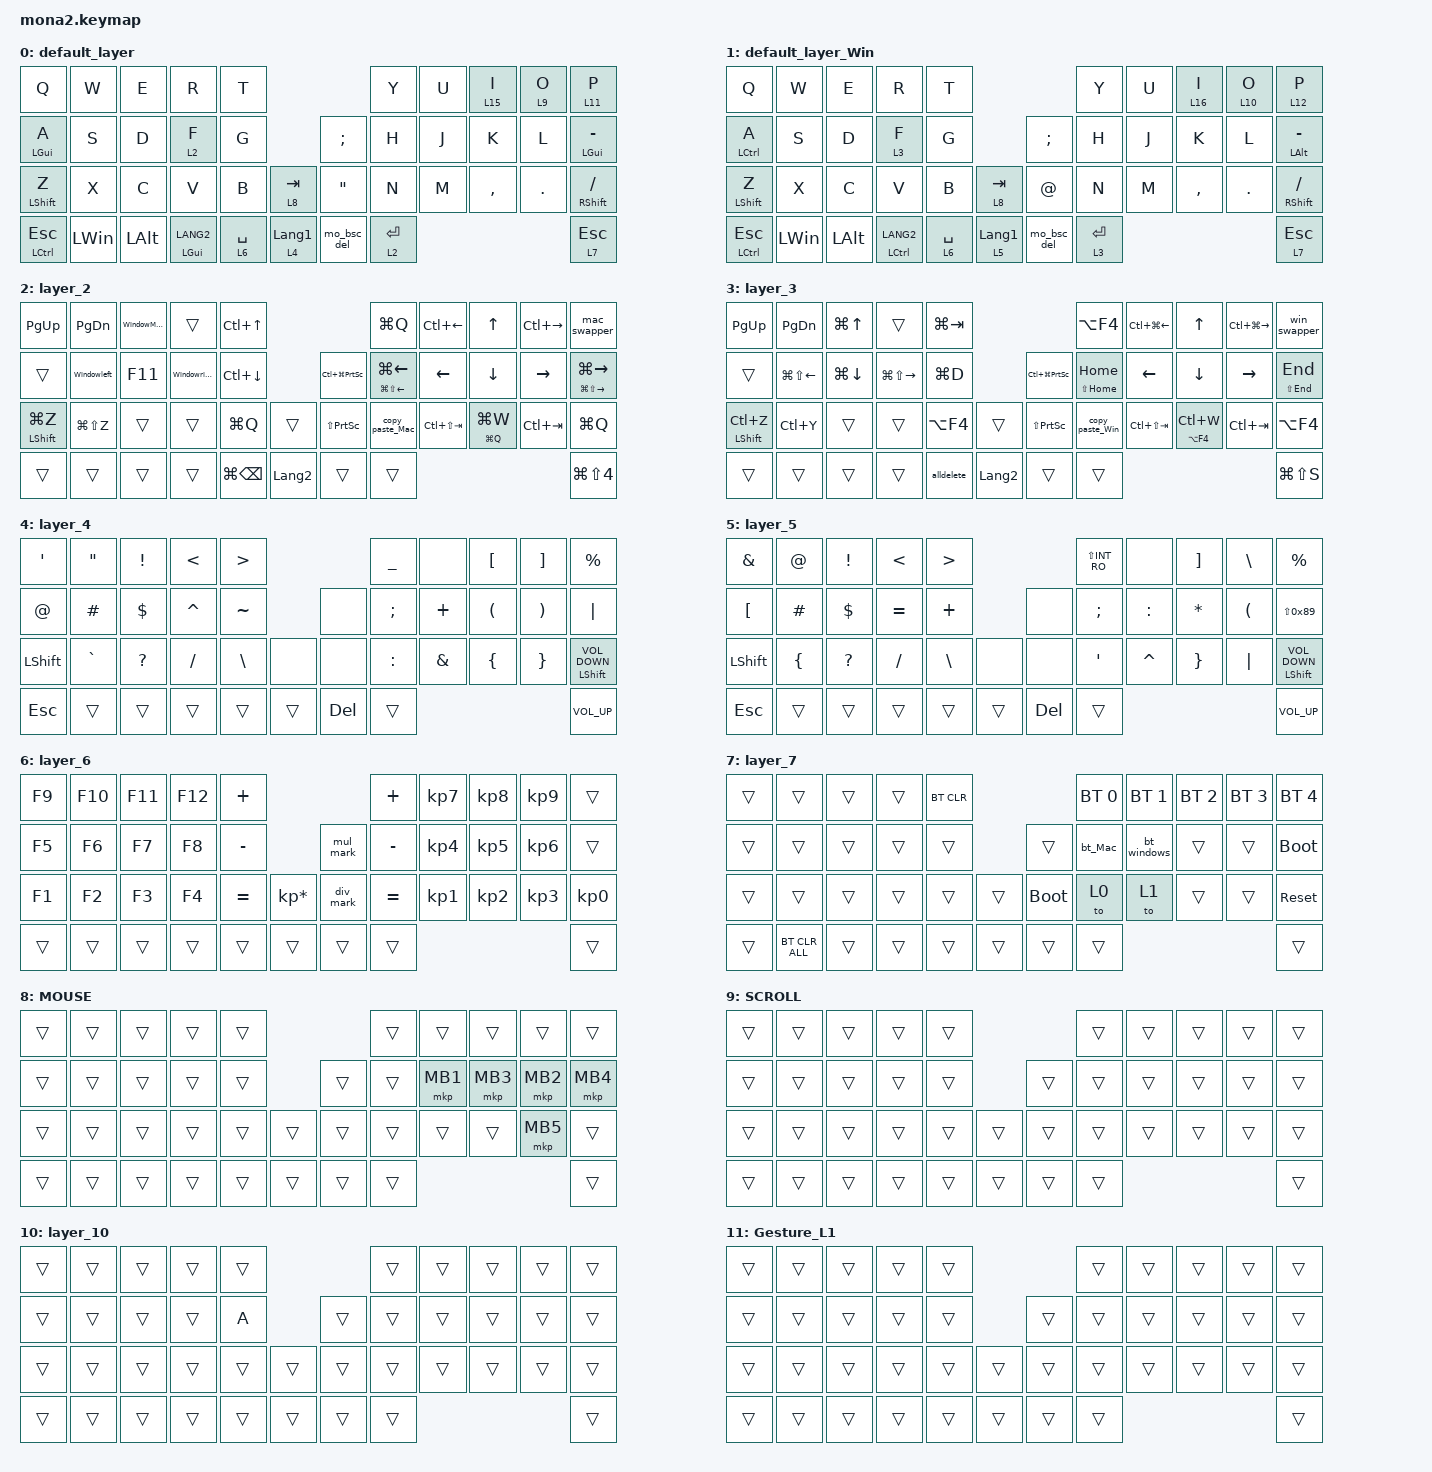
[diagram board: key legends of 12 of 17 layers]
#include <input/processors.dtsi>
#include <dt-bindings/zmk/input_transform.h>
#include <zephyr/dt-bindings/input/input-event-codes.h>
#include <mouse-gesture.dtsi>
#include <zephyr/dt-bindings/input/input-event-codes.h>
#include <behaviors.dtsi>
#include <dt-bindings/zmk/bt.h>
#include <dt-bindings/zmk/keys.h>
#include <dt-bindings/zmk/pointing.h>

//#include "gesture/gesture_L1.dtsi"
//#include "gesture/gesture_L2.dtsi"
//#include "gesture/gesture_L3.dtsi"

#define ZMK_POINTING_DEFAULT_SCRL_VAL 100
#define MOUSE 5

// OS設定を日本語キーボードのまま使用するための変換定義

#define JP_DQUOTE       AT                // "
#define JP_AMPERSAND    CARET             // &
#define JP_QUOTE        AMPERSAND         // '
#define JP_EQUAL        UNDER             // =
#define JP_CARET        EQUAL             // ^
#define JP_YEN          0x89              // ¥
#define JP_PLUS         COLON             // +
#define JP_TILDE        PLUS              // ~
#define JP_PIPE         LS(0x89)          // |
#define JP_AT           LEFT_BRACKET      // @
#define JP_COLON        SINGLE_QUOTE      // :
#define JP_ASTERISK     DOUBLE_QUOTES     // *
#define JP_BACKQUOTE    LEFT_BRACE        // `
#define JP_UNDERSCORE   LS(0x87)          // _
#define JP_LBRACKET     RIGHT_BRACKET     // [
#define JP_RBRACKET     BACKSLASH         // ]
#define JP_LPAREN       ASTERISK          // (
#define JP_RPAREN       LEFT_PARENTHESIS  // )
#define JP_LBRACE       RIGHT_BRACE       // {
#define JP_RBRACE       PIPE              // }
#define JP_KANA         LANGUAGE_1        // かな
#define JP_EISU         LANGUAGE_2        // 英数
#define JP_HANZEN       GRAVE             // 半角/全角

&mt {
    flavor = "balanced";
    quick-tap-ms = <250>;
};

&lt {
    tapping-term-ms = <180>; /* タップ判定時間 */
    quick-tap-ms = <200>; /* クイックタップ時間(連続タップ判定時間) */
    flavor = "balanced";
};

/ {
    combos {
        compatible = "zmk,combos";

        a {
            bindings = <&none>;
            key-positions = <17 29 18 19 31 10 21>;
        };

        tab {
            bindings = <&kp TAB>;
            key-positions = <11 12>;
        };

        esc {
            bindings = <&kp ESC>;
            key-positions = <2 1>;
        };

        f10 {
            bindings = <&kp F10>;
            key-positions = <23 24>;
        };

        Layer13 {
            bindings = <&lt 13 LG(TAB)>;
            key-positions = <8 9>;
            layers = <0>;
        };

        Layer15 {
            bindings = <&kp TAB>;
            key-positions = <19 18>;
            layers = <0 1 8>;
        };

        layer14 {
            bindings = <&lt 14 LA(TAB)>;
            key-positions = <8 9>;
            layers = <1>;
        };

        Spotlight {
            bindings = <&kp LG(SPACE)>;
            key-positions = <8 7>;
            layers = <0>;
        };

        search {
            bindings = <&kp LEFT_GUI>;
            key-positions = <8 7>;
            layers = <1>;
        };

        command_c {
            bindings = <&command_c>;
            key-positions = <18 17>;
            layers = <2>;
        };

        command_v {
            bindings = <&command_v>;
            key-positions = <18 19>;
            layers = <2>;
        };

        control_c {
            bindings = <&control_c>;
            key-positions = <18 17>;
            layers = <3>;
        };

        control_v {
            bindings = <&control_v>;
            key-positions = <18 19>;
            layers = <3>;
        };

        command_z {
            bindings = <&kp LG(Z)>;
            key-positions = <21 22>;
            layers = <0>;
        };

        control_z {
            bindings = <&kp LC(Z)>;
            key-positions = <21 22>;
            layers = <1>;
        };

        command_y {
            bindings = <&kp LG(LS(Z))>;
            key-positions = <22 23>;
            layers = <0>;
        };

        control_y {
            bindings = <&kp LC(Y)>;
            key-positions = <22 23>;
            layers = <1>;
        };

        missioncontrol {
            bindings = <&missioncontrol>;
            key-positions = <7 8>;
            layers = <2>;
        };

        Windows_tab {
            bindings = <&window_tab>;
            key-positions = <7 8>;
            layers = <3>;
        };

        buck {
            bindings = <&mkp MB4>;
            key-positions = <30 31>;
        };

        Buck2 {
            bindings = <&mkp MB4>;
            key-positions = <29 30>;
        };

        Layer7 {
            bindings = <&mo 7>;
            key-positions = <33 34>;
        };
    };

    macros {
        to_layer_0: to_layer_0 {
            compatible = "zmk,behavior-macro-one-param";
            #binding-cells = <1>;
            bindings = <&to 0 &macro_param_1to1 &kp MACRO_PLACEHOLDER>;
            label = "TO_LAYER_0";
        };

        mul_mark: x_sign_win {
            compatible = "zmk,behavior-macro";
            #binding-cells = <0>;
            wait-ms = <10>;
            tap-ms = <10>;
            bindings =
                <&macro_press>,
                <&kp LALT>,
                <&macro_tap>,
                <&kp KP_N0 &kp KP_N2 &kp KP_N1 &kp KP_N5>,
                <&macro_release>,
                <&kp LALT>;
        };

        div_mark: div_mark {
            compatible = "zmk,behavior-macro";
            label = "DIV_MARK";
            #binding-cells = <0>;
            wait-ms = <10>;
            tap-ms = <10>;
            bindings =
                <&macro_press>,
                <&kp LALT>,
                <&macro_tap>,
                <&kp KP_N0 &kp KP_N2 &kp KP_N4 &kp KP_N7>,
                <&macro_release>,
                <&kp LALT>;
        };

        exit_AML: exit_AML {
            compatible = "zmk,behavior-macro";
            wait-ms = <0>;
            tap-ms = <0>;
            #binding-cells = <0>;
            bindings = <&tog_off 9>;
            label = "exit_AML";
        };

        kp_exit_AML: kp_exit_AML {
            compatible = "zmk,behavior-macro-one-param";
            wait-ms = <0>;
            tap-ms = <0>;
            #binding-cells = <1>;
            bindings = <&macro_param_1to1 &kp MACRO_PLACEHOLDER &exit_AML>;
            label = "KP_exit_AML";
        };

        bt_Mac: bt_Mac {
            compatible = "zmk,behavior-macro";
            #binding-cells = <0>;
            bindings = <&macro_tap>, <&bt BT_SEL 0>, <&macro_tap>, <&to 0>;

            label = "BT_MAC";
        };

        bt_windows: bt_windows {
            compatible = "zmk,behavior-macro";
            #binding-cells = <0>;
            bindings = <&macro_tap>, <&bt BT_SEL 1>, <&macro_tap>, <&to 1>;

            label = "BT_WINDOWS";
        };

        WindowMaximize: WindowMaximize {
            compatible = "zmk,behavior-macro";
            #binding-cells = <0>;
            bindings =
                <&macro_press>,
                <&kp LCTRL &kp LEFT_ALT>,
                <&macro_tap>,
                <&kp ENTER>,
                <&macro_release>,
                <&kp LCTRL &kp LEFT_ALT>;

            label = "WINDOWMAXIMIZE";
        };

        Windowleft: Windowleft {
            compatible = "zmk,behavior-macro";
            #binding-cells = <0>;
            bindings =
                <&macro_press>,
                <&kp LCTRL &kp LEFT_ALT>,
                <&macro_tap>,
                <&kp LEFT_ARROW>,
                <&macro_release>,
                <&kp LCTRL &kp LEFT_ALT>;

            label = "WINDOWLEFT";
        };

        Windowright: Windowright {
            compatible = "zmk,behavior-macro";
            #binding-cells = <0>;
            bindings =
                <&macro_press>,
                <&kp LCTRL &kp LEFT_ALT>,
                <&macro_tap>,
                <&kp RIGHT_ARROW>,
                <&macro_release>,
                <&kp LCTRL &kp LEFT_ALT>;

            label = "WINDOWRIGHT";
        };

        alldelete: alldelete {
            compatible = "zmk,behavior-macro";
            #binding-cells = <0>;
            bindings =
                <&macro_press>,
                <&kp LSHFT>,
                <&macro_tap>,
                <&kp HOME>,
                <&macro_release>,
                <&kp LSHFT>,
                <&macro_tap>,
                <&kp BACKSPACE>;

            label = "ALLDELETE";
        };
    };

    behaviors {
        lt_to_layer_0: lt_to_layer_0 {
            compatible = "zmk,behavior-hold-tap";
            label = "LAYER_TAP_TO_0";
            #binding-cells = <2>;
            tapping-term-ms = <200>;
            bindings = <&mo>, <&to_layer_0>;
        };

        scroll_up_down: mouse_wheel_up_down {
            compatible = "zmk,behavior-sensor-rotate";
            #sensor-binding-cells = <0>;
            tap-ms = <20>;
            bindings = <&msc SCRL_DOWN>, <&msc SCRL_UP>;
        };

        scroll_right_left: mouse_wheel_right_left {
            compatible = "zmk,behavior-sensor-rotate";
            #sensor-binding-cells = <0>;
            tap-ms = <20>;
            bindings = <&msc SCRL_LEFT>, <&msc SCRL_RIGHT>;
        };

        tog_off: toggle_layer_off {
            compatible = "zmk,behavior-toggle-layer";
            #binding-cells = <1>;
            display-name = "Toggle Layer Off";
            toggle-mode = "off";
        };

        mt_exit_AML_on_tap: mt_exit_AML_on_tap {
            compatible = "zmk,behavior-hold-tap";
            label = "MT_exit_AML_ON_TAP";
            bindings = <&kp>, <&kp_exit_AML>;

            #binding-cells = <2>;
            tapping-term-ms = <200>;
            flavor = "balanced";
            quick-tap-ms = <200>;
        };

        eisu_kana: eisu_kana {
            compatible = "zmk,behavior-tap-dance";
            label = "EISU_KANA";
            #binding-cells = <0>;
            bindings = <&lt 6 LANGUAGE_1>, <&kp LANGUAGE_2>;

            tapping-term-ms = <180>;
        };

        copy_paste_Mac: copy_paste_Mac {
            compatible = "zmk,behavior-tap-dance";
            label = "COPY_PASTE_MAC";
            #binding-cells = <0>;
            tapping-term-ms = <250>;
            bindings = <&mt LG(X) LG(C)>, <&kp LG(V)>;
        };

        copy_paste_Win: copy_paste_Win {
            compatible = "zmk,behavior-tap-dance";
            label = "COPY_PASTE_WIN";
            #binding-cells = <0>;
            tapping-term-ms = <250>;
            bindings = <&mt LC(X) LC(C)>, <&kp LC(V)>;
        };

        new_behavior: new_behavior {
            compatible = "zmk,behavior-sensor-rotate-var";
            label = "NEW_BEHAVIOR";
            #sensor-binding-cells = <2>;
            bindings = <&kp>, <&kp>;
        };

        missioncontrol: missioncontrol {
            compatible = "zmk,behavior-tap-dance";
            label = "MISSIONCONTROL";
            #binding-cells = <0>;
            bindings = <&kp LC(UP_ARROW)>, <&kp LC(DOWN_ARROW)>;

            tapping-term-ms = <250>;
        };

        window_tab: window_tab {
            compatible = "zmk,behavior-tap-dance";
            label = "WINDOW_TAB";
            #binding-cells = <0>;
            bindings = <&kp LG(TAB)>, <&kp LG(D)>;

            tapping-term-ms = <250>;
        };

        command_c: command_c {
            compatible = "zmk,behavior-tap-dance";
            label = "COMMAND_C";
            #binding-cells = <0>;
            tapping-term-ms = <250>;
            bindings = <&kp LG(C)>, <&kp LG(X)>;
        };

        command_v: command_v {
            compatible = "zmk,behavior-tap-dance";
            label = "COMMAND_V";
            #binding-cells = <0>;
            tapping-term-ms = <250>;
            bindings = <&kp LG(V)>, <&kp LG(V)>;
        };

        control_c: control_c {
            compatible = "zmk,behavior-tap-dance";
            label = "CONTROL_C";
            #binding-cells = <0>;
            tapping-term-ms = <250>;
            bindings = <&kp LC(C)>, <&kp LC(X)>;
        };

        control_v: control_v {
            compatible = "zmk,behavior-tap-dance";
            label = "CONTROL_V";
            #binding-cells = <0>;
            tapping-term-ms = <250>;
            bindings = <&kp LC(V)>, <&kp LG(V)>;
        };

        scroll_up_down_win: scroll_up_down_win {
            compatible = "zmk,behavior-sensor-rotate";
            #sensor-binding-cells = <0>;
            tap-ms = <20>;
            bindings = <&msc SCRL_UP>, <&msc SCRL_DOWN>;

            label = "SCROLL_UP_DOWN_WIN";
        };

        // 「マック・スワッパー」の定義

        mac_swapper: mac_swapper {
            compatible = "zmk,behavior-smart-toggle";
            #binding-cells = <0>;
            bindings = <&kp LGUI>, <&kp TAB>;

            // 1つ目がホールド(Cmd)、2つ目が連打用(Tab)
            // ignored-key-positions = <8>;     // 隣のキー（逆送り用）を指定。※環境に合わせて番号を調整してください
        };

        win_swapper: win_swapper {
            compatible = "zmk,behavior-smart-toggle";
            #binding-cells = <0>;
            bindings = <&kp LALT>, <&kp TAB>;

            // ignored-key-positions = <8>;
        };

        mo_bsc_del: mo_bsc_del {
            compatible = "zmk,behavior-mod-morph";
            label = "MO_BSC_DEL";
            bindings = <&kp BACKSPACE>, <&kp DELETE>;

            #binding-cells = <0>;
            mods = <(MOD_RSFT|MOD_LSFT)>;
        };
    };

    keymap {
        compatible = "zmk,keymap";

        default_layer {
            bindings = <
&kp Q             &kp W         &kp E         &kp R               &kp T                                               &kp Y        &kp U  &lt 15 I   &lt 9 O  &lt 11 P
&mt LEFT_GUI A    &kp S         &kp D         &lt 2 F             &kp G                            &kp SEMICOLON      &kp H        &kp J  &kp K      &kp L    &mt LEFT_GUI MINUS
&mt LEFT_SHIFT Z  &kp X         &kp C         &kp V               &kp B        &lt 8 TAB           &kp DOUBLE_QUOTES  &kp N        &kp M  &kp COMMA  &kp DOT  &mt RIGHT_SHIFT SLASH
&mt LCTRL ESC     &kp LEFT_WIN  &kp LEFT_ALT  &mt LEFT_GUI LANG2  &lt 6 SPACE  &lt 4 LANGUAGE_1    &mo_bsc_del        &lt 2 ENTER                             &lt 7 ESCAPE
            >;

            sensor-bindings = <&scroll_up_down>;
        };

        default_layer_Win {
            bindings = <
&kp Q             &kp W         &kp E         &kp R                   &kp T                                           &kp Y        &kp U  &lt 16 I   &lt 10 O  &lt 12 P
&mt LCTRL A       &kp S         &kp D         &lt 3 F                 &kp G                            &kp SEMICOLON  &kp H        &kp J  &kp K      &kp L     &mt LEFT_ALT MINUS
&mt LEFT_SHIFT Z  &kp X         &kp C         &kp V                   &kp B        &lt 8 TAB           &kp AT_SIGN    &kp N        &kp M  &kp COMMA  &kp DOT   &mt RIGHT_SHIFT SLASH
&mt LCTRL ESC     &kp LEFT_WIN  &kp LEFT_ALT  &mt LEFT_CONTROL LANG2  &lt 6 SPACE  &lt 5 LANGUAGE_1    &mo_bsc_del    &lt 3 ENTER                              &lt 7 ESC
            >;

            sensor-bindings = <&scroll_up_down_win>;
        };

        layer_2 {
            bindings = <
&kp PAGE_UP      &kp PAGE_DOWN  &WindowMaximize  &trans        &kp LC(UP_ARROW)                                               &kp LG(Q)                              &kp LC(LEFT_ARROW)  &kp UP_ARROW     &kp LC(RIGHT_ARROW)  &mac_swapper
&trans           &Windowleft    &kp F11          &Windowright  &kp LC(DOWN_ARROW)                    &kp LC(LG(PRINTSCREEN))  &mt LG(LS(LEFT_ARROW)) LG(LEFT_ARROW)  &kp LEFT_ARROW      &kp DOWN_ARROW   &kp RIGHT_ARROW      &mt LG(LS(RIGHT_ARROW)) LG(RIGHT_ARROW)
&mt LSHFT LG(Z)  &kp LG(LS(Z))  &trans           &trans        &kp LG(Q)           &trans            &kp LS(PRINTSCREEN)      &copy_paste_Mac                        &kp LC(LS(TAB))     &mt LG(Q) LG(W)  &kp LC(TAB)          &kp LG(Q)
&trans           &trans         &trans           &trans        &kp LG(BACKSPACE)   &kp LANGUAGE_2    &trans                   &trans                                                                                           &kp LG(LS(NUMBER_4))
            >;

            sensor-bindings = <&inc_dec_kp LC(LS(TAB)) LC(TAB)>;
        };

        layer_3 {
            bindings = <
&kp PAGE_UP      &kp PAGE_DOWN     &kp LG(UP_ARROW)  &trans                   &kp LG(TAB)                                             &kp LA(F4)         &kp LC(LG(LEFT_ARROW))  &kp UP_ARROW      &kp LC(LG(RIGHT_ARROW))  &win_swapper
&trans           &kp LG(LS(LEFT))  &kp LG(DOWN)      &kp LG(LS(RIGHT_ARROW))  &kp LG(D)                      &kp LC(LG(PRINTSCREEN))  &mt LS(HOME) HOME  &kp LEFT_ARROW          &kp DOWN_ARROW    &kp RIGHT_ARROW          &mt LS(END) END
&mt LSHFT LC(Z)  &kp LC(Y)         &trans            &trans                   &kp LA(F4)   &trans            &kp LS(PRINTSCREEN)      &copy_paste_Win    &kp LC(LS(TAB))         &mt LA(F4) LC(W)  &kp LC(TAB)              &kp LA(F4)
&trans           &trans            &trans            &trans                   &alldelete   &kp LANGUAGE_2    &trans                   &trans                                                                                &kp LG(LS(S))
            >;

            sensor-bindings = <&inc_dec_kp LC(LS(TAB)) LC(TAB)>;
        };

        layer_4 {
            bindings = <
&kp SINGLE_QUOTE  &kp DOUBLE_QUOTES  &kp EXCLAMATION  &kp LESS_THAN  &kp GREATER_THAN                        &kp UNDERSCORE  &none     &kp LEFT_BRACKET      &kp RIGHT_BRACKET      &kp PERCENT
&kp AT_SIGN       &kp HASH           &kp DOLLAR       &kp CARET      &kp TILDE                   &none       &kp SEMICOLON   &kp PLUS  &kp LEFT_PARENTHESIS  &kp RIGHT_PARENTHESIS  &kp PIPE
&kp LSHIFT        &kp GRAVE          &kp QUESTION     &kp SLASH      &kp BACKSLASH     &none     &none       &kp COLON       &kp AMPS  &kp LEFT_BRACE        &kp RIGHT_BRACE        &mt LSHFT C_VOLUME_DOWN
&kp ESC           &trans             &trans           &trans         &trans            &trans    &kp DELETE  &trans                                                                 &kp C_VOLUME_UP
            >;

            sensor-bindings = <&inc_dec_kp LEFT_ARROW RIGHT_ARROW>;
        };

        layer_5 {
            bindings = <
&kp AMPS          &kp AT_SIGN     &kp EXCLAMATION  &kp LESS_THAN  &kp GREATER_THAN                        &kp LS(INT_RO)    &none      &kp RIGHT_BRACKET  &kp BACKSLASH         &kp PERCENT
&kp LEFT_BRACKET  &kp HASH        &kp DOLLAR       &kp EQUAL      &kp PLUS                    &none       &kp SEMICOLON     &kp COLON  &kp ASTERISK       &kp LEFT_PARENTHESIS  &kp LS(0x89)
&kp LSHIFT        &kp LEFT_BRACE  &kp QUESTION     &kp SLASH      &kp BACKSLASH     &none     &none       &kp SINGLE_QUOTE  &kp CARET  &kp RIGHT_BRACE    &kp PIPE              &mt LSHFT C_VOLUME_DOWN
&kp ESC           &trans          &trans           &trans         &trans            &trans    &kp DELETE  &trans                                                                &kp C_VOLUME_UP
            >;

            sensor-bindings = <&scroll_right_left>;
        };

        layer_6 {
            bindings = <
&kp F9  &kp F10  &kp F11  &kp F12  &kp PLUS                                 &kp PLUS   &kp KP_NUMBER_7  &kp KP_NUMBER_8  &kp KP_NUMBER_9  &trans
&kp F5  &kp F6   &kp F7   &kp F8   &kp MINUS                     &mul_mark  &kp MINUS  &kp KP_NUMBER_4  &kp KP_NUMBER_5  &kp KP_NUMBER_6  &trans
&kp F1  &kp F2   &kp F3   &kp F4   &kp EQUAL  &kp KP_MULTIPLY    &div_mark  &kp EQUAL  &kp KP_NUMBER_1  &kp KP_NUMBER_2  &kp KP_NUMBER_3  &kp KP_NUMBER_0
&trans  &trans   &trans   &trans   &trans     &trans             &trans     &trans                                                        &trans
            >;

            sensor-bindings = <&scroll_up_down>;
        };

        layer_7 {
            bindings = <
&trans  &trans          &trans  &trans  &bt BT_CLR                         &bt BT_SEL 0  &bt BT_SEL 1  &bt BT_SEL 2  &bt BT_SEL 3  &bt BT_SEL 4
&trans  &trans          &trans  &trans  &trans                &trans       &bt_Mac       &bt_windows   &trans        &trans        &bootloader
&trans  &trans          &trans  &trans  &trans      &trans    &bootloader  &to 0         &to 1         &trans        &trans        &sys_reset
&trans  &bt BT_CLR_ALL  &trans  &trans  &trans      &trans    &trans       &trans                                                  &trans
            >;

            sensor-bindings = <&scroll_up_down>;
        };

        MOUSE {
            bindings = <
&trans  &trans  &trans  &trans  &trans                    &trans  &trans    &trans    &trans    &trans
&trans  &trans  &trans  &trans  &trans            &trans  &trans  &mkp MB1  &mkp MB3  &mkp MB2  &mkp MB4
&trans  &trans  &trans  &trans  &trans  &trans    &trans  &trans  &trans    &trans    &mkp MB5  &trans
&trans  &trans  &trans  &trans  &trans  &trans    &trans  &trans                                &trans
            >;

            sensor-bindings = <&scroll_up_down>;
        };

        SCROLL {
            bindings = <
&trans  &trans  &trans  &trans  &trans                    &trans  &trans  &trans  &trans  &trans
&trans  &trans  &trans  &trans  &trans            &trans  &trans  &trans  &trans  &trans  &trans
&trans  &trans  &trans  &trans  &trans  &trans    &trans  &trans  &trans  &trans  &trans  &trans
&trans  &trans  &trans  &trans  &trans  &trans    &trans  &trans                          &trans
            >;

            sensor-bindings = <&inc_dec_kp LEFT_ARROW RIGHT_ARROW>;
        };

        layer_10 {
            bindings = <
&trans  &trans  &trans  &trans  &trans                    &trans  &trans  &trans  &trans  &trans
&trans  &trans  &trans  &trans  &kp A             &trans  &trans  &trans  &trans  &trans  &trans
&trans  &trans  &trans  &trans  &trans  &trans    &trans  &trans  &trans  &trans  &trans  &trans
&trans  &trans  &trans  &trans  &trans  &trans    &trans  &trans                          &trans
            >;

            sensor-bindings = <&inc_dec_kp LEFT_ARROW RIGHT_ARROW>;
        };

        Gesture_L1 {
            bindings = <
&trans  &trans  &trans  &trans  &trans                    &trans  &trans  &trans  &trans  &trans
&trans  &trans  &trans  &trans  &trans            &trans  &trans  &trans  &trans  &trans  &trans
&trans  &trans  &trans  &trans  &trans  &trans    &trans  &trans  &trans  &trans  &trans  &trans
&trans  &trans  &trans  &trans  &trans  &trans    &trans  &trans                          &trans
            >;

            sensor-bindings = <&inc_dec_kp UP_ARROW DOWN_ARROW>;
        };

        Gesture_L2 {
            bindings = <
&trans  &trans  &trans  &trans  &trans                    &trans  &trans  &trans  &trans  &trans
&trans  &trans  &trans  &trans  &trans            &trans  &trans  &trans  &trans  &trans  &trans
&trans  &trans  &trans  &trans  &trans  &trans    &trans  &trans  &trans  &trans  &trans  &trans
&trans  &trans  &trans  &trans  &trans  &trans    &trans  &trans                          &trans
            >;

            sensor-bindings = <&inc_dec_kp UP_ARROW DOWN_ARROW>;
        };

        Gesture_L3 {
            bindings = <
&trans  &trans  &trans  &trans  &trans                    &trans  &trans  &trans  &trans  &trans
&trans  &trans  &trans  &trans  &trans            &trans  &trans  &trans  &trans  &trans  &trans
&trans  &trans  &trans  &trans  &trans  &trans    &trans  &trans  &trans  &trans  &trans  &trans
&trans  &trans  &trans  &trans  &trans  &trans    &trans  &trans                          &trans
            >;
        };

        layer_14 {
            bindings = <
&trans  &trans  &trans  &trans  &trans                    &trans  &trans  &trans  &trans  &trans
&trans  &trans  &trans  &trans  &trans            &trans  &trans  &trans  &trans  &trans  &trans
&trans  &trans  &trans  &trans  &trans  &trans    &trans  &trans  &trans  &trans  &trans  &trans
&trans  &trans  &trans  &trans  &trans  &trans    &trans  &trans                          &trans
            >;
        };

        layer_15 {
            bindings = <
&trans  &trans  &trans  &trans  &trans                    &trans  &trans  &trans  &trans  &trans
&trans  &trans  &trans  &trans  &trans            &trans  &trans  &trans  &trans  &trans  &trans
&trans  &trans  &trans  &trans  &trans  &trans    &trans  &trans  &trans  &trans  &trans  &trans
&trans  &trans  &trans  &trans  &trans  &trans    &trans  &trans                          &trans
            >;
        };

        layer_16 {
            bindings = <
&trans  &trans  &trans  &trans  &trans                    &trans  &trans  &trans  &trans  &trans
&trans  &trans  &trans  &trans  &trans            &trans  &trans  &trans  &trans  &trans  &trans
&trans  &trans  &trans  &trans  &trans  &trans    &trans  &trans  &trans  &trans  &trans  &trans
&trans  &trans  &trans  &trans  &trans  &trans    &trans  &trans                          &trans
            >;
        };
    };
};

// ジェスチャー設定 
// L11用のパターン

&zip_mouse_gesture_1 {
    enable-eager-mode;
    always-active;
    stroke-size = <5>;
    movement-threshold = <6>;
    idle-timeout-ms = <100>;
    gesture-cooldown-ms = <120>;

    prev_tab_l11 {
        pattern = <GESTURE_LEFT>;
        bindings = <&kp LC(LS(TAB))>;
    };

    next_tab_l11 {
        pattern = <GESTURE_RIGHT>;
        bindings = <&kp LC(TAB)>;
    };

    Create_tab_l11 {
        pattern = <GESTURE_UP>;
        bindings = <&kp LG(T)>;
    };

    close_tab_l11 {
        pattern = <GESTURE_DOWN>;
        bindings = <&kp LG(W)>;
    };
};

// L12用のパターン

&zip_mouse_gesture_2 {
    enable-eager-mode;
    always-active;
    stroke-size = <5>;
    movement-threshold = <6>;
    idle-timeout-ms = <100>;
    gesture-cooldown-ms = <120>;

    prev_tab_l12 {
        pattern = <GESTURE_LEFT>;
        bindings = <&kp LC(LS(TAB))>;
    };

    next_tab_l12 {
        pattern = <GESTURE_RIGHT>;
        bindings = <&kp LC(TAB)>;
    };

    Create_tab_l12 {
        pattern = <GESTURE_UP>;
        bindings = <&kp LC(T)>;
    };

    close_tab_l12 {
        pattern = <GESTURE_DOWN>;
        bindings = <&kp LC(W)>;
    };
};

// L13用のパターン(ウィンドウ操作_Mac)

&zip_mouse_gesture_3 {
    enable-eager-mode;
    always-active;
    stroke-size = <5>;
    movement-threshold = <6>;
    idle-timeout-ms = <100>;
    gesture-cooldown-ms = <120>;

    vdesk_prev_13 {
        pattern = <GESTURE_LEFT>;
        bindings = <&kp LC(LEFT)>;
    };

    vdesk_next_13 {
        pattern = <GESTURE_RIGHT>;
        bindings = <&kp LC(RIGHT)>;
    };

    view_window_13 {
        pattern = <GESTURE_UP>;
        bindings = <&kp LC(UP)>;
    };

    view_application_13 {
        pattern = <GESTURE_DOWN>;
        bindings = <&kp LC(DOWN)>;
    };
};

// L14用のパターン(ウィンドウ操作_win)

&zip_mouse_gesture_4 {
    enable-eager-mode;
    always-active;
    stroke-size = <5>;
    movement-threshold = <6>;
    idle-timeout-ms = <100>;
    gesture-cooldown-ms = <120>;

    vdesk_prev_14 {
        pattern = <GESTURE_LEFT>;
        bindings = <&kp LG(LC(LEFT))>;
    };

    vdesk_next_14 {
        pattern = <GESTURE_RIGHT>;
        bindings = <&kp LG(LC(RIGHT))>;
    };

    view_window_14 {
        pattern = <GESTURE_UP>;
        bindings = <&kp LG(TAB)>;
    };

    view_application_14 {
        pattern = <GESTURE_DOWN>;
        bindings = <&kp LG(D)>;
    };
};

// L15用のパターン

&zip_mouse_gesture_5 {
    enable-eager-mode;
    always-active;
    stroke-size = <5>;
    movement-threshold = <6>;
    idle-timeout-ms = <100>;
    gesture-cooldown-ms = <120>;

    copy_15 {
        pattern = <GESTURE_LEFT>;
        bindings = <&kp LG(C)>;
    };

    paste_15 {
        pattern = <GESTURE_RIGHT>;
        bindings = <&kp LG(V)>;
    };

    focus_url_15 {
        pattern = <GESTURE_UP>;
        bindings = <&kp LG(L)>;
    };

    search_15 {
        pattern = <GESTURE_DOWN>;
        bindings = <&kp LG(SPACE)>;
    };
};

// L16用のパターン ※準備中

&zip_mouse_gesture_6 {
    enable-eager-mode;
    always-active;
    stroke-size = <5>;
    movement-threshold = <6>;
    idle-timeout-ms = <100>;
    gesture-cooldown-ms = <120>;

    copy_16 {
        pattern = <GESTURE_LEFT>;
        bindings = <&kp LC(C)>;
    };

    paste_16 {
        pattern = <GESTURE_RIGHT>;
        bindings = <&kp LC(V)>;
    };

    focus_url_16 {
        pattern = <GESTURE_UP>;
        bindings = <&kp LC(L)>;
    };

    search_16 {
        pattern = <GESTURE_DOWN>;
        bindings = <&kp LGUI>;
    };
};
